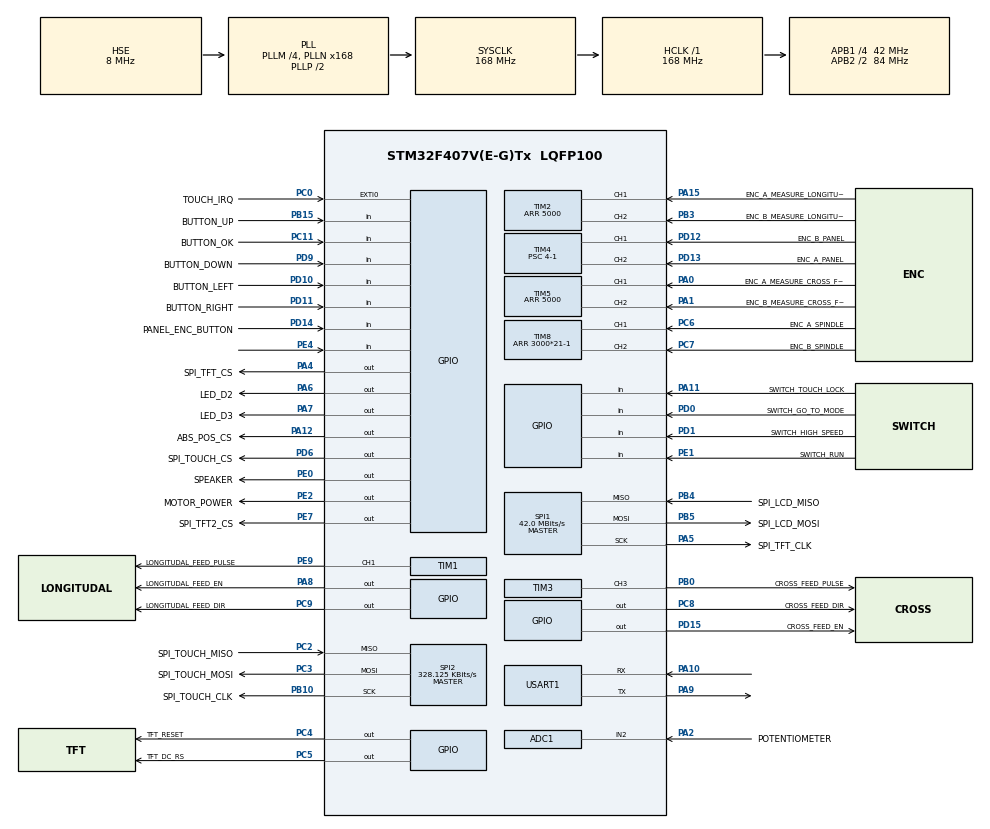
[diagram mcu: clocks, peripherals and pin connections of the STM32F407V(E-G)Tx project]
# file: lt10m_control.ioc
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ADC1.Channel-3\#ChannelRegularConversion=ADC_CHANNEL_2
ADC1.ClockPrescaler=ADC_CLOCK_SYNC_PCLK_DIV8
ADC1.ContinuousConvMode=DISABLE
ADC1.EOCSelection=ADC_EOC_SEQ_CONV
ADC1.NbrOfConversion=1
ADC1.NbrOfConversionFlag=1
ADC1.Rank-3\#ChannelRegularConversion=1
ADC1.SamplingTime-3\#ChannelRegularConversion=ADC_SAMPLETIME_3CYCLES
ADC1.master=1
Dma.Request0=SPI1_TX
Dma.SPI1_TX.0.Direction=DMA_MEMORY_TO_PERIPH
Dma.SPI1_TX.0.FIFOMode=DMA_FIFOMODE_DISABLE
Dma.SPI1_TX.0.Instance=DMA2_Stream3
Dma.SPI1_TX.0.MemDataAlignment=DMA_MDATAALIGN_BYTE
Dma.SPI1_TX.0.MemInc=DMA_MINC_ENABLE
Dma.SPI1_TX.0.Mode=DMA_NORMAL
Dma.SPI1_TX.0.PeriphDataAlignment=DMA_PDATAALIGN_BYTE
Dma.SPI1_TX.0.PeriphInc=DMA_PINC_DISABLE
Dma.SPI1_TX.0.Priority=DMA_PRIORITY_LOW
FREERTOS.Tasks01=defaultTask,24,128,StartDefaultTask,Default,NULL,Dynamic,NULL,NULL
FREERTOS.configUSE_PREEMPTION=0
Mcu.Family=STM32F4
Mcu.Name=STM32F407V(E-G)Tx
Mcu.Package=LQFP100
NVIC.DMA2_Stream3_IRQn=true\:5\:0\:false\:false\:true\:true\:false\:true\:true
NVIC.EXTI0_IRQn=true\:5\:0\:false\:false\:true\:true\:true\:true\:true
NVIC.PriorityGroup=NVIC_PRIORITYGROUP_4
NVIC.TIM2_IRQn=true\:5\:0\:false\:false\:true\:true\:true\:true\:true
NVIC.TIM5_IRQn=true\:5\:0\:false\:false\:true\:true\:true\:true\:true
NVIC.TIM6_DAC_IRQn=true\:5\:0\:false\:false\:true\:true\:true\:true\:true
PA0-WKUP.GPIO_Label=ENC_A_MEASURE_CROSS_FEED
PA0-WKUP.GPIO_PuPd=GPIO_PULLUP
PA0-WKUP.GPIO_Speed=GPIO_SPEED_FREQ_HIGH
PA0-WKUP.Signal=S_TIM5_CH1
PA1.GPIO_Label=ENC_B_MEASURE_CROSS_FEED
PA1.GPIO_PuPd=GPIO_PULLUP
PA1.GPIO_Speed=GPIO_SPEED_FREQ_HIGH
PA1.Signal=S_TIM5_CH2
PA10.Mode=Asynchronous
PA10.Signal=USART1_RX
PA11.GPIO_Label=SWITCH_TOUCH_LOCK
PA11.GPIO_PuPd=GPIO_PULLUP
PA11.Signal=GPIO_Input
PA12.GPIO_Label=ABS_POS_CS
PA12.Signal=GPIO_Output
PA15.GPIO_Label=ENC_A_MEASURE_LONGITUDAL_FEED
PA15.GPIO_PuPd=GPIO_PULLUP
PA15.GPIO_Speed=GPIO_SPEED_FREQ_HIGH
PA15.Signal=S_TIM2_CH1_ETR
PA2.GPIO_Label=POTENTIOMETER
PA2.GPIO_PuPd=GPIO_NOPULL
PA2.Signal=ADCx_IN2
PA4.GPIO_Label=SPI_TFT_CS
PA4.GPIO_Speed=GPIO_SPEED_FREQ_VERY_HIGH
PA4.PinState=GPIO_PIN_SET
PA4.Signal=GPIO_Output
PA5.GPIO_Label=SPI_TFT_CLK
PA5.Mode=Full_Duplex_Master
PA5.Signal=SPI1_SCK
PA6.GPIO_Label=LED_D2
PA6.Signal=GPIO_Output
PA7.GPIO_Label=LED_D3
PA7.Signal=GPIO_Output
PA8.GPIO_Label=LONGITUDAL_FEED_EN
PA8.PinState=GPIO_PIN_SET
PA8.Signal=GPIO_Output
PA9.Mode=Asynchronous
PA9.Signal=USART1_TX
PB0.GPIO_Label=CROSS_FEED_PULSE
PB0.GPIO_PuPd=GPIO_PULLDOWN
PB0.Signal=S_TIM3_CH3
PB10.GPIO_Label=SPI_TOUCH_CLK
PB10.Mode=Full_Duplex_Master
PB10.Signal=SPI2_SCK
PB15.GPIO_Label=BUTTON_UP
PB15.GPIO_PuPd=GPIO_PULLUP
PB15.Signal=GPIO_Input
PB3.GPIO_Label=ENC_B_MEASURE_LONGITUDAL_FEED
PB3.GPIO_PuPd=GPIO_PULLUP
PB3.GPIO_Speed=GPIO_SPEED_FREQ_HIGH
PB3.Signal=S_TIM2_CH2
PB4.GPIO_Label=SPI_LCD_MISO
PB4.Mode=Full_Duplex_Master
PB4.Signal=SPI1_MISO
PB5.GPIO_Label=SPI_LCD_MOSI
PB5.Mode=Full_Duplex_Master
PB5.Signal=SPI1_MOSI
PC0.GPIO_Label=TOUCH_IRQ
PC0.GPIO_ModeDefaultEXTI=GPIO_MODE_IT_FALLING
PC0.GPIO_PuPd=GPIO_PULLUP
PC0.Signal=GPXTI0
PC11.GPIO_Label=BUTTON_OK
PC11.GPIO_PuPd=GPIO_PULLUP
PC11.Signal=GPIO_Input
PC2.GPIO_Label=SPI_TOUCH_MISO
PC2.Mode=Full_Duplex_Master
PC2.Signal=SPI2_MISO
PC3.GPIO_Label=SPI_TOUCH_MOSI
PC3.Mode=Full_Duplex_Master
PC3.Signal=SPI2_MOSI
PC4.GPIO_Label=TFT_RESET
PC4.PinState=GPIO_PIN_RESET
PC4.Signal=GPIO_Output
PC5.GPIO_Label=TFT_DC_RS
PC5.Signal=GPIO_Output
PC6.GPIO_Label=ENC_A_SPINDLE
PC6.GPIO_PuPd=GPIO_PULLUP
PC6.Signal=S_TIM8_CH1
PC7.GPIO_Label=ENC_B_SPINDLE
PC7.GPIO_PuPd=GPIO_PULLUP
PC7.Signal=S_TIM8_CH2
PC8.GPIO_Label=CROSS_FEED_DIR
PC8.Signal=GPIO_Output
PC9.GPIO_Label=LONGITUDAL_FEED_DIR
PC9.Signal=GPIO_Output
PD0.GPIO_Label=SWITCH_GO_TO_MODE
PD0.GPIO_PuPd=GPIO_PULLUP
PD0.Signal=GPIO_Input
PD1.GPIO_Label=SWITCH_HIGH_SPEED
PD1.GPIO_PuPd=GPIO_PULLUP
PD1.Signal=GPIO_Input
PD10.GPIO_Label=BUTTON_LEFT
PD10.GPIO_PuPd=GPIO_PULLUP
PD10.Signal=GPIO_Input
PD11.GPIO_Label=BUTTON_RIGHT
PD11.GPIO_PuPd=GPIO_PULLUP
PD11.Signal=GPIO_Input
PD12.GPIO_Label=ENC_B_PANEL
PD12.GPIO_PuPd=GPIO_PULLUP
PD12.Signal=S_TIM4_CH1
PD13.GPIO_Label=ENC_A_PANEL
PD13.GPIO_PuPd=GPIO_PULLUP
PD13.Signal=S_TIM4_CH2
PD14.GPIO_Label=PANEL_ENC_BUTTON
PD14.GPIO_PuPd=GPIO_PULLUP
PD14.Signal=GPIO_Input
PD15.GPIO_Label=CROSS_FEED_EN
PD15.PinState=GPIO_PIN_SET
PD15.Signal=GPIO_Output
PD6.GPIO_Label=SPI_TOUCH_CS
PD6.PinState=GPIO_PIN_SET
PD6.Signal=GPIO_Output
PD9.GPIO_Label=BUTTON_DOWN
PD9.GPIO_PuPd=GPIO_PULLUP
PD9.Signal=GPIO_Input
PE0.GPIO_Label=SPEAKER
PE0.Signal=GPIO_Output
PE1.GPIO_Label=SWITCH_RUN
PE1.GPIO_PuPd=GPIO_PULLUP
PE1.Signal=GPIO_Input
PE2.GPIO_Label=MOTOR_POWER
PE2.Signal=GPIO_Output
PE4.Signal=GPIO_Input
PE7.GPIO_Label=SPI_TFT2_CS
PE7.GPIO_Speed=GPIO_SPEED_FREQ_VERY_HIGH
PE7.PinState=GPIO_PIN_SET
PE7.Signal=GPIO_Output
PE9.GPIO_Label=LONGITUDAL_FEED_PULSE
PE9.GPIO_PuPd=GPIO_PULLDOWN
PE9.Signal=S_TIM1_CH1
PH0-OSC_IN.Mode=HSE-External-Oscillator
PH0-OSC_IN.Signal=RCC_OSC_IN
PH1-OSC_OUT.Mode=HSE-External-Oscillator
PH1-OSC_OUT.Signal=RCC_OSC_OUT
ProjectManager.HeapSize=0x19000
ProjectManager.StackSize=0x400
ProjectManager.TargetToolchain=STM32CubeIDE
RCC.48MHZClocksFreq_Value=84000000
RCC.AHBFreq_Value=168000000
RCC.APB1CLKDivider=RCC_HCLK_DIV4
RCC.APB1Freq_Value=42000000
RCC.APB1TimFreq_Value=84000000
RCC.APB2CLKDivider=RCC_HCLK_DIV2
RCC.APB2Freq_Value=84000000
RCC.APB2TimFreq_Value=168000000
RCC.CortexFreq_Value=168000000
RCC.HCLKFreq_Value=168000000
RCC.HSE_VALUE=8000000
RCC.HSI_VALUE=16000000
RCC.LSE_VALUE=32768
RCC.PLLM=4
RCC.PLLN=168
RCC.PLLSourceVirtual=RCC_PLLSOURCE_HSE
RCC.SYSCLKFreq_VALUE=168000000
RCC.SYSCLKSource=RCC_SYSCLKSOURCE_PLLCLK
RCC.VCOOutputFreq_Value=336000000
SH.ADCx_IN2.0=ADC1_IN2,IN2
SH.S_TIM1_CH1.0=TIM1_CH1,PWM Generation1 CH1
SH.S_TIM2_CH1_ETR.0=TIM2_CH1,Encoder_Interface
SH.S_TIM2_CH2.0=TIM2_CH2,Encoder_Interface
SH.S_TIM3_CH3.0=TIM3_CH3,PWM Generation3 CH3
SH.S_TIM4_CH1.0=TIM4_CH1,Encoder_Interface
SH.S_TIM4_CH2.0=TIM4_CH2,Encoder_Interface
SH.S_TIM5_CH1.0=TIM5_CH1,Encoder_Interface
SH.S_TIM5_CH2.0=TIM5_CH2,Encoder_Interface
SH.S_TIM8_CH1.0=TIM8_CH1,Encoder_Interface
SH.S_TIM8_CH2.0=TIM8_CH2,Encoder_Interface
SPI1.BaudRatePrescaler=SPI_BAUDRATEPRESCALER_2
SPI1.CalculateBaudRate=42.0 MBits/s
SPI1.Direction=SPI_DIRECTION_2LINES
SPI1.FirstBit=SPI_FIRSTBIT_MSB
SPI1.Mode=SPI_MODE_MASTER
SPI1.VirtualType=VM_MASTER
SPI2.BaudRatePrescaler=SPI_BAUDRATEPRESCALER_128
SPI2.CLKPhase=SPI_PHASE_1EDGE
SPI2.CalculateBaudRate=328.125 KBits/s
SPI2.Direction=SPI_DIRECTION_2LINES
SPI2.Mode=SPI_MODE_MASTER
SPI2.VirtualType=VM_MASTER
TIM1.AutoReloadPreload=TIM_AUTORELOAD_PRELOAD_ENABLE
TIM1.Channel-PWM\ Generation1\ CH1=TIM_CHANNEL_1
TIM1.OC1Preload_PWM=DISABLE
TIM1.OCPolarity_1=TIM_OCPOLARITY_LOW
TIM1.Period=1000
TIM1.Prescaler=168-1
TIM1.Pulse-PWM\ Generation1\ CH1=1
TIM1.TIM_MasterOutputTrigger=TIM_TRGO_UPDATE
TIM1.TIM_MasterSlaveMode=TIM_MASTERSLAVEMODE_ENABLE
TIM2.ClockDivision=TIM_CLOCKDIVISION_DIV2
TIM2.EncoderMode=TIM_ENCODERMODE_TI12
TIM2.IC1Filter=15
TIM2.IC1Polarity=TIM_ICPOLARITY_FALLING
TIM2.IC2Filter=15
TIM2.IC2Polarity=TIM_ICPOLARITY_FALLING
TIM2.Period=5000
TIM2.TIM_MasterOutputTrigger=TIM_TRGO_ENABLE
TIM2.TIM_MasterSlaveMode=TIM_MASTERSLAVEMODE_ENABLE
TIM3.AutoReloadPreload=TIM_AUTORELOAD_PRELOAD_ENABLE
TIM3.Channel-PWM\ Generation3\ CH3=TIM_CHANNEL_3
TIM3.OC3Preload_PWM=DISABLE
TIM3.OCPolarity_3=TIM_OCPOLARITY_LOW
TIM3.Period=1000
TIM3.Prescaler=84-1
TIM3.Pulse-PWM\ Generation3\ CH3=1
TIM3.TIM_MasterOutputTrigger=TIM_TRGO_UPDATE
TIM3.TIM_MasterSlaveMode=TIM_MASTERSLAVEMODE_ENABLE
TIM4.ClockDivision=TIM_CLOCKDIVISION_DIV4
TIM4.EncoderMode=TIM_ENCODERMODE_TI12
TIM4.IC1Filter=15
TIM4.IC1Polarity=TIM_ICPOLARITY_RISING
TIM4.IC2Filter=15
TIM4.IC2Polarity=TIM_ICPOLARITY_FALLING
TIM4.Period=0xFFFF-1
TIM4.Prescaler=4-1
TIM5.ClockDivision=TIM_CLOCKDIVISION_DIV2
TIM5.EncoderMode=TIM_ENCODERMODE_TI12
TIM5.IC1Filter=15
TIM5.IC1Polarity=TIM_ICPOLARITY_FALLING
TIM5.IC2Filter=15
TIM5.IC2Polarity=TIM_ICPOLARITY_RISING
TIM5.Period=5000
TIM5.TIM_MasterOutputTrigger=TIM_TRGO_ENABLE
TIM5.TIM_MasterSlaveMode=TIM_MASTERSLAVEMODE_ENABLE
TIM6.Period=1000-1
TIM6.Prescaler=84-1
TIM6.TIM_MasterOutputTrigger=TIM_TRGO_UPDATE
TIM7.Prescaler=84-1
TIM8.ClockDivision=TIM_CLOCKDIVISION_DIV2
TIM8.EncoderMode=TIM_ENCODERMODE_TI12
TIM8.IC1Filter=15
TIM8.IC1Polarity=TIM_ICPOLARITY_FALLING
TIM8.IC2Filter=15
TIM8.IC2Polarity=TIM_ICPOLARITY_FALLING
TIM8.Period=3000*21-1
USART1.VirtualMode=VM_ASYNC
VP_FREERTOS_VS_CMSIS_V2.Mode=CMSIS_V2
VP_TIM1_VS_ClockSourceINT.Mode=Internal
VP_TIM1_VS_ClockSourceITR.Mode=TriggerSource_ITR1
VP_TIM1_VS_ControllerModeGated.Mode=Gated Mode
VP_TIM2_VS_OPM.Mode=OPM_bit
VP_TIM3_VS_ClockSourceINT.Mode=Internal
VP_TIM3_VS_ClockSourceITR.Mode=TriggerSource_ITR2
VP_TIM3_VS_ControllerModeGated.Mode=Gated Mode
VP_TIM5_VS_OPM.Mode=OPM_bit
VP_TIM6_VS_ClockSourceINT.Mode=Enable_Timer
VP_TIM7_VS_ClockSourceINT.Mode=Enable_Timer
board=custom

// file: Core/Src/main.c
/* USER CODE BEGIN Header */
/**
  ******************************************************************************
  * @file           : main.c
  * @brief          : Main program body
  ******************************************************************************
  * @attention
  *
  * Copyright (c) 2025 STMicroelectronics.
  * All rights reserved.
  *
  * This software is licensed under terms that can be found in the LICENSE file
  * in the root directory of this software component.
  * If no LICENSE file comes with this software, it is provided AS-IS.
  *
  ******************************************************************************
  */
/* USER CODE END Header */
#include "main.h"
#include "cmsis_os.h"
#include "adc.h"
#include "dma.h"
#include "spi.h"
#include "tim.h"
#include "usart.h"
#include "gpio.h"

/* USER CODE BEGIN Includes */
#include "machine/machine.h"
/* USER CODE END Includes */

void SystemClock_Config(void);
void MX_FREERTOS_Init(void);

int main(void)
{

  /* MCU Configuration--------------------------------------------------------*/

  /* Reset of all peripherals, Initializes the Flash interface and the Systick. */
  HAL_Init();

  /* Configure the system clock */
  SystemClock_Config();

  /* Initialize all configured peripherals */
  MX_GPIO_Init();
  MX_DMA_Init();
  MX_USART1_UART_Init();
  MX_TIM1_Init();
  MX_SPI1_Init();
  MX_SPI2_Init();
  MX_TIM2_Init();
  MX_TIM3_Init();
  MX_ADC1_Init();
  MX_TIM4_Init();
  MX_TIM5_Init();
  MX_TIM6_Init();
  MX_TIM7_Init();
  MX_TIM8_Init();

  /* Init scheduler */
  osKernelInitialize();  /* Call init function for freertos objects (in freertos.c) */
  MX_FREERTOS_Init();

  /* Start scheduler */
  osKernelStart();

  /* We should never get here as control is now taken by the scheduler */
  /* Infinite loop */
  while (1)
  {

  }
}

void SystemClock_Config(void)
{
  RCC_OscInitTypeDef RCC_OscInitStruct = {0};
  RCC_ClkInitTypeDef RCC_ClkInitStruct = {0};

  /** Configure the main internal regulator output voltage
  */
  __HAL_RCC_PWR_CLK_ENABLE();
  __HAL_PWR_VOLTAGESCALING_CONFIG(PWR_REGULATOR_VOLTAGE_SCALE1);

  /** Initializes the RCC Oscillators according to the specified parameters
  * in the RCC_OscInitTypeDef structure.
  */
  RCC_OscInitStruct.OscillatorType = RCC_OSCILLATORTYPE_HSE;
  RCC_OscInitStruct.HSEState = RCC_HSE_ON;
  RCC_OscInitStruct.PLL.PLLState = RCC_PLL_ON;
  RCC_OscInitStruct.PLL.PLLSource = RCC_PLLSOURCE_HSE;
  RCC_OscInitStruct.PLL.PLLM = 4;
  RCC_OscInitStruct.PLL.PLLN = 168;
  RCC_OscInitStruct.PLL.PLLP = RCC_PLLP_DIV2;
  RCC_OscInitStruct.PLL.PLLQ = 4;
  if (HAL_RCC_OscConfig(&RCC_OscInitStruct) != HAL_OK)
  {
    Error_Handler();
  }

  /** Initializes the CPU, AHB and APB buses clocks
  */
  RCC_ClkInitStruct.ClockType = RCC_CLOCKTYPE_HCLK|RCC_CLOCKTYPE_SYSCLK
                              |RCC_CLOCKTYPE_PCLK1|RCC_CLOCKTYPE_PCLK2;
  RCC_ClkInitStruct.SYSCLKSource = RCC_SYSCLKSOURCE_PLLCLK;
  RCC_ClkInitStruct.AHBCLKDivider = RCC_SYSCLK_DIV1;
  RCC_ClkInitStruct.APB1CLKDivider = RCC_HCLK_DIV4;
  RCC_ClkInitStruct.APB2CLKDivider = RCC_HCLK_DIV2;

  if (HAL_RCC_ClockConfig(&RCC_ClkInitStruct, FLASH_LATENCY_5) != HAL_OK)
  {
    Error_Handler();
  }
}

void Error_Handler(void)
{
  __disable_irq();
  while (1)
  {
  }
}

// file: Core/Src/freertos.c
/* USER CODE BEGIN Header */
/**
  ******************************************************************************
  * File Name          : freertos.c
  * Description        : Code for freertos applications
  ******************************************************************************
  * @attention
  *
  * Copyright (c) 2025 STMicroelectronics.
  * All rights reserved.
  *
  * This software is licensed under terms that can be found in the LICENSE file
  * in the root directory of this software component.
  * If no LICENSE file comes with this software, it is provided AS-IS.
  *
  ******************************************************************************
  */
/* USER CODE END Header */

#include "FreeRTOS.h"
#include "task.h"
#include "main.h"
#include "cmsis_os.h"

/* USER CODE BEGIN Includes */
#include "machine/machine.h"
/* USER CODE END Includes */

/* Definitions for defaultTask */
osThreadId_t defaultTaskHandle;
const osThreadAttr_t defaultTask_attributes = {
  .name = "defaultTask",
  .stack_size = 128 * 4,
  .priority = (osPriority_t) osPriorityNormal,
};

void StartDefaultTask(void *argument);

void MX_FREERTOS_Init(void); /* (MISRA C 2004 rule 8.1) */

void MX_FREERTOS_Init(void) {

  /* Create the thread(s) */
  /* creation of defaultTask */
  defaultTaskHandle = osThreadNew(StartDefaultTask, NULL, &defaultTask_attributes);

  /* USER CODE BEGIN RTOS_THREADS */
  /* add threads, ... */
  machine_init();
  /* USER CODE END RTOS_THREADS */

}

void StartDefaultTask(void *argument)
{
  for(;;)
  {
    osDelay(1);
  }
}
